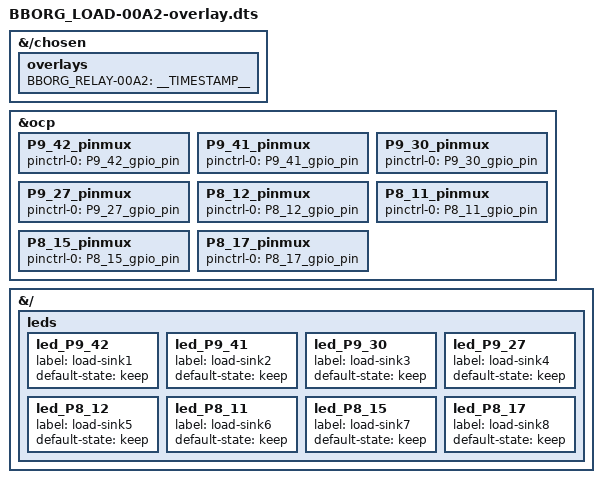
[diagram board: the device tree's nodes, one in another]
/*
 * Copyright (C) 2020 Deepak Khatri <deepaklorkhatri7@gmail.com>
 *
 * This program is free software; you can redistribute it and/or modify
 * it under the terms of the GNU General Public License version 2 as
 * published by the Free Software Foundation.
 */

/dts-v1/;
/plugin/;

/*
 * Helper to show loaded overlays under: /proc/device-tree/chosen/overlays/
 */
&{/chosen} {
	overlays {
		BBORG_RELAY-00A2 = __TIMESTAMP__;
	};
};

/*
 * Free up the pins used by the cape from the pinmux helpers.
 */
&ocp {
	P9_42_pinmux { status = "disabled"; };  /* Sink1 */
	P9_41_pinmux { status = "disabled"; };  /* Sink2 */
	P9_30_pinmux { status = "disabled"; };  /* Sink3 */
	P9_27_pinmux { status = "disabled"; };	/* Sink4 */
	P8_12_pinmux { status = "disabled"; };  /* Sink5 */
	P8_11_pinmux { status = "disabled"; };	/* Sink6 */
	P8_15_pinmux { status = "disabled"; };  /* Sink7 */
	P8_17_pinmux { status = "disabled"; };	/* Sink8 */
};

/*
 * Enable and Update the default state of the pins
 */
&ocp {
	P9_42_pinmux { status = "okay"; pinctrl-0 = <&P9_42_gpio_pin>; };	/* Sink1 */
	P9_41_pinmux { status = "okay"; pinctrl-0 = <&P9_41_gpio_pin>; };	/* Sink2 */
	P9_30_pinmux { status = "okay"; pinctrl-0 = <&P9_30_gpio_pin>; };	/* Sink3 */
	P9_27_pinmux { status = "okay"; pinctrl-0 = <&P9_27_gpio_pin>; };	/* Sink4 */
	P8_12_pinmux { status = "okay"; pinctrl-0 = <&P8_12_gpio_pin>; };	/* Sink5 */
	P8_11_pinmux { status = "okay"; pinctrl-0 = <&P8_11_gpio_pin>; };	/* Sink6 */
	P8_15_pinmux { status = "okay"; pinctrl-0 = <&P8_15_gpio_pin>; };	/* Sink7 */
	P8_17_pinmux { status = "okay"; pinctrl-0 = <&P8_17_gpio_pin>; };	/* Sink8 */
};

/*
 * Easy load control through sysfs (/sys/class/leds/) using gpio-leds driver
 * See these files for the led_P8_#/led_P9_#  definition
 * https://github.com/beagleboard/BeagleBoard-DeviceTrees/src/arm/bbai-bone-buses.dtsi
 * https://github.com/beagleboard/BeagleBoard-DeviceTrees/src/arm/bbb-bone-buses.dtsi
 *
 */
&{/} {
	leds {
		led_P9_42 {
			status = "okay";
			label = "load-sink1";
			default-state = "keep";
		};

		led_P9_41 {
			status = "okay";
			label = "load-sink2";
			default-state = "keep";
		};

		led_P9_30 {
			status = "okay";
			label = "load-sink3";
			default-state = "keep";
		};

		led_P9_27 {
			status = "okay";
			label = "load-sink4";
			default-state = "keep";
		};

		led_P8_12 {
			status = "okay";
			label = "load-sink5";
			default-state = "keep";
		};

		led_P8_11 {
			status = "okay";
			label = "load-sink6";
			default-state = "keep";
		};

		led_P8_15 {
			status = "okay";
			label = "load-sink7";
			default-state = "keep";
		};

		led_P8_17 {
			status = "okay";
			label = "load-sink8";
			default-state = "keep";
		};
	};
};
